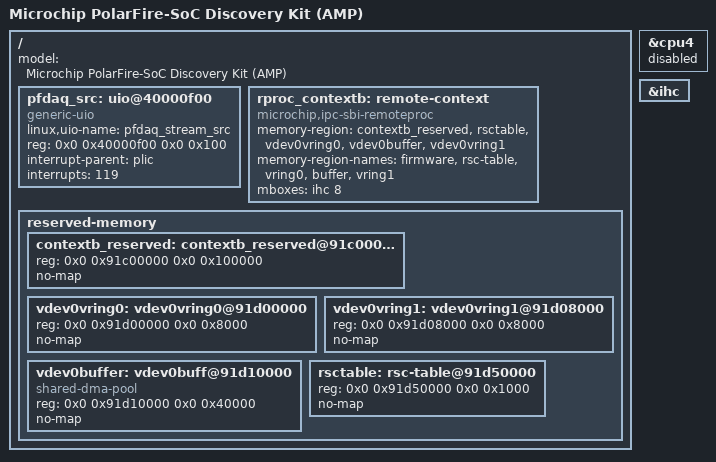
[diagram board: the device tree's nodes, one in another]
// SPDX-License-Identifier: (GPL-2.0 OR MIT)
/*
 * PolarFire SoC Discovery Kit, AMP configuration:
 * Linux on U54_1-3, context B (FreeRTOS or bare metal) on U54_4.
 * Regions and nodes follow dt-overlay-mchp mpfs_icicle/mpfs_icicle_amp.dtso.
 * MMUART0 (context B console) and wdt4 are already disabled in mpfs-disco-kit.dts.
 */

#include "mpfs-disco-kit.dts"

/ {
	model = "Microchip PolarFire-SoC Discovery Kit (AMP)";

	/*
	 * Project fabric: pfdaq_core APB registers, stream source + latency unit (FIC3 slot 0x40000F00, added by
	 * hw/libero/overlay/PFDAQ.tcl).
	 * Exposed through UIO; map one page and add offset 0xF00.
	 */
	pfdaq_src: uio@40000f00 {
		compatible = "generic-uio";
		linux,uio-name = "pfdaq_stream_src";
		reg = <0x0 0x40000f00 0x0 0x100>;
		/* latency unit channel 0: fabric F2M[1] = PLIC source 119 (118 + F2M index) */
		interrupt-parent = <&plic>;
		interrupts = <119>;
	};

	rproc_contextb: remote-context {
		compatible = "microchip,ipc-sbi-remoteproc";
		memory-region = <&contextb_reserved>, <&rsctable>,
				<&vdev0vring0>, <&vdev0buffer>,
				<&vdev0vring1>;
		memory-region-names = "firmware", "rsc-table",
				      "vring0", "buffer", "vring1";
		mboxes = <&ihc 8>;
		status = "okay";
	};

	reserved-memory {
		contextb_reserved: contextb_reserved@91c00000 {
			reg = <0x0 0x91c00000 0x0 0x100000>;
			no-map;
		};

		vdev0vring0: vdev0vring0@91d00000 {
			reg = <0x0 0x91d00000 0x0 0x8000>;
			no-map;
		};

		vdev0vring1: vdev0vring1@91d08000 {
			reg = <0x0 0x91d08000 0x0 0x8000>;
			no-map;
		};

		vdev0buffer: vdev0buff@91d10000 {
			compatible = "shared-dma-pool";
			reg = <0x0 0x91d10000 0x0 0x40000>;
			no-map;
		};

		rsctable: rsc-table@91d50000 {
			reg = <0x0 0x91d50000 0x0 0x1000>;
			no-map;
		};
	};
};

&cpu4 {
	status = "disabled"; /* owned by context B */
};

&ihc {
	status = "okay";
};
